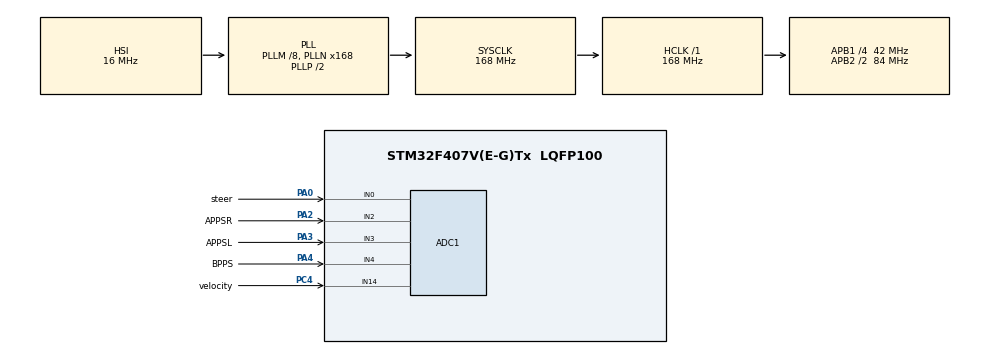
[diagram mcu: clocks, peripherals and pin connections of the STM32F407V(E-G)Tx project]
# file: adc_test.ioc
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ADC1.Channel-0\#ChannelRegularConversion=ADC_CHANNEL_2
ADC1.Channel-1\#ChannelRegularConversion=ADC_CHANNEL_3
ADC1.Channel-2\#ChannelRegularConversion=ADC_CHANNEL_4
ADC1.Channel-3\#ChannelRegularConversion=ADC_CHANNEL_0
ADC1.Channel-4\#ChannelInjectedConversion=ADC_CHANNEL_0
ADC1.Channel-5\#ChannelInjectedConversion=ADC_CHANNEL_0
ADC1.Channel-6\#ChannelInjectedConversion=ADC_CHANNEL_0
ADC1.Channel-7\#ChannelInjectedConversion=ADC_CHANNEL_0
ADC1.ClockPrescaler=ADC_CLOCK_SYNC_PCLK_DIV8
ADC1.ContinuousConvMode=ENABLE
ADC1.DMAContinuousRequests=ENABLE
ADC1.InjNumberOfConversion=4
ADC1.InjectedOffset-4\#ChannelInjectedConversion=0
ADC1.InjectedOffset-5\#ChannelInjectedConversion=0
ADC1.InjectedOffset-6\#ChannelInjectedConversion=0
ADC1.InjectedOffset-7\#ChannelInjectedConversion=0
ADC1.InjectedRank-4\#ChannelInjectedConversion=1
ADC1.InjectedRank-5\#ChannelInjectedConversion=2
ADC1.InjectedRank-6\#ChannelInjectedConversion=3
ADC1.InjectedRank-7\#ChannelInjectedConversion=4
ADC1.NbrOfConversion=4
ADC1.NbrOfConversionFlag=1
ADC1.Rank-0\#ChannelRegularConversion=1
ADC1.Rank-1\#ChannelRegularConversion=2
ADC1.Rank-2\#ChannelRegularConversion=3
ADC1.Rank-3\#ChannelRegularConversion=4
ADC1.SamplingTime-0\#ChannelRegularConversion=ADC_SAMPLETIME_112CYCLES
ADC1.SamplingTime-1\#ChannelRegularConversion=ADC_SAMPLETIME_112CYCLES
ADC1.SamplingTime-2\#ChannelRegularConversion=ADC_SAMPLETIME_112CYCLES
ADC1.SamplingTime-3\#ChannelRegularConversion=ADC_SAMPLETIME_112CYCLES
ADC1.SamplingTime-4\#ChannelInjectedConversion=ADC_SAMPLETIME_3CYCLES
ADC1.SamplingTime-5\#ChannelInjectedConversion=ADC_SAMPLETIME_3CYCLES
ADC1.SamplingTime-6\#ChannelInjectedConversion=ADC_SAMPLETIME_3CYCLES
ADC1.SamplingTime-7\#ChannelInjectedConversion=ADC_SAMPLETIME_3CYCLES
ADC1.ScanConvMode=ENABLE
ADC1.master=1
Dma.ADC1.0.Direction=DMA_PERIPH_TO_MEMORY
Dma.ADC1.0.FIFOMode=DMA_FIFOMODE_DISABLE
Dma.ADC1.0.Instance=DMA2_Stream0
Dma.ADC1.0.MemDataAlignment=DMA_MDATAALIGN_HALFWORD
Dma.ADC1.0.MemInc=DMA_MINC_ENABLE
Dma.ADC1.0.Mode=DMA_CIRCULAR
Dma.ADC1.0.PeriphDataAlignment=DMA_PDATAALIGN_HALFWORD
Dma.ADC1.0.PeriphInc=DMA_PINC_DISABLE
Dma.ADC1.0.Priority=DMA_PRIORITY_LOW
Dma.Request0=ADC1
Mcu.Family=STM32F4
Mcu.Name=STM32F407V(E-G)Tx
Mcu.Package=LQFP100
NVIC.DMA2_Stream0_IRQn=true\:0\:0\:false\:false\:true\:false\:true
NVIC.PriorityGroup=NVIC_PRIORITYGROUP_4
PA0-WKUP.GPIO_Label=steer
PA0-WKUP.Signal=ADCx_IN0
PA2.GPIO_Label=APPSR
PA2.Signal=ADCx_IN2
PA3.GPIO_Label=APPSL
PA3.Signal=ADCx_IN3
PA4.GPIO_Label=BPPS
PA4.Signal=ADCx_IN4
PC4.GPIO_Label=velocity
PC4.Signal=ADCx_IN14
PH0-OSC_IN.Mode=HSE-External-Oscillator
PH0-OSC_IN.Signal=RCC_OSC_IN
PH1-OSC_OUT.Mode=HSE-External-Oscillator
PH1-OSC_OUT.Signal=RCC_OSC_OUT
ProjectManager.HeapSize=0x200
ProjectManager.StackSize=0x400
ProjectManager.TargetToolchain=MDK-ARM V5.32
RCC.48MHZClocksFreq_Value=84000000
RCC.AHBFreq_Value=168000000
RCC.APB1CLKDivider=RCC_HCLK_DIV4
RCC.APB1Freq_Value=42000000
RCC.APB1TimFreq_Value=84000000
RCC.APB2CLKDivider=RCC_HCLK_DIV2
RCC.APB2Freq_Value=84000000
RCC.APB2TimFreq_Value=168000000
RCC.CortexFreq_Value=168000000
RCC.HCLKFreq_Value=168000000
RCC.HSE_VALUE=25000000
RCC.HSI_VALUE=16000000
RCC.LSE_VALUE=32768
RCC.PLLM=8
RCC.PLLN=168
RCC.SYSCLKFreq_VALUE=168000000
RCC.SYSCLKSource=RCC_SYSCLKSOURCE_PLLCLK
RCC.VCOOutputFreq_Value=336000000
SH.ADCx_IN0.0=ADC1_IN0,IN0
SH.ADCx_IN14.0=ADC1_IN14,IN14
SH.ADCx_IN2.0=ADC1_IN2,IN2
SH.ADCx_IN3.0=ADC1_IN3,IN3
SH.ADCx_IN4.0=ADC1_IN4,IN4
board=custom

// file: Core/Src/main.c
/* USER CODE BEGIN Header */
/**
  ******************************************************************************
  * @file           : main.c
  * @brief          : Main program body
  ******************************************************************************
  * @attention
  *
  * <h2><center>&copy; Copyright (c) 2021 STMicroelectronics.
  * All rights reserved.</center></h2>
  *
  * This software component is licensed by ST under BSD 3-Clause license,
  * the "License"; You may not use this file except in compliance with the
  * License. You may obtain a copy of the License at:
  *                        opensource.org/licenses/BSD-3-Clause
  *
  ******************************************************************************
  */
/* USER CODE END Header */
#include "main.h"
#include "adc.h"
#include "dma.h"
#include "gpio.h"

/* USER CODE BEGIN PV */
uint8_t adcArr[4];

/* USER CODE END PV */

void SystemClock_Config(void);

int main(void)
{

  /* MCU Configuration--------------------------------------------------------*/

  /* Reset of all peripherals, Initializes the Flash interface and the Systick. */
  HAL_Init();

  /* Configure the system clock */
  SystemClock_Config();

  /* Initialize all configured peripherals */
  MX_GPIO_Init();
  MX_DMA_Init();
  MX_ADC1_Init();
  /* USER CODE BEGIN 2 */
	HAL_ADC_Start_DMA(&hadc1,(uint32_t*)adcArr,4);
  /* USER CODE END 2 */

  /* Infinite loop */
  while (1)
  {

  }
}

void SystemClock_Config(void)
{
  RCC_OscInitTypeDef RCC_OscInitStruct = {0};
  RCC_ClkInitTypeDef RCC_ClkInitStruct = {0};

  /** Configure the main internal regulator output voltage
  */
  __HAL_RCC_PWR_CLK_ENABLE();
  __HAL_PWR_VOLTAGESCALING_CONFIG(PWR_REGULATOR_VOLTAGE_SCALE1);
  /** Initializes the RCC Oscillators according to the specified parameters
  * in the RCC_OscInitTypeDef structure.
  */
  RCC_OscInitStruct.OscillatorType = RCC_OSCILLATORTYPE_HSI;
  RCC_OscInitStruct.HSIState = RCC_HSI_ON;
  RCC_OscInitStruct.HSICalibrationValue = RCC_HSICALIBRATION_DEFAULT;
  RCC_OscInitStruct.PLL.PLLState = RCC_PLL_ON;
  RCC_OscInitStruct.PLL.PLLSource = RCC_PLLSOURCE_HSI;
  RCC_OscInitStruct.PLL.PLLM = 8;
  RCC_OscInitStruct.PLL.PLLN = 168;
  RCC_OscInitStruct.PLL.PLLP = RCC_PLLP_DIV2;
  RCC_OscInitStruct.PLL.PLLQ = 4;
  if (HAL_RCC_OscConfig(&RCC_OscInitStruct) != HAL_OK)
  {
    Error_Handler();
  }
  /** Initializes the CPU, AHB and APB buses clocks
  */
  RCC_ClkInitStruct.ClockType = RCC_CLOCKTYPE_HCLK|RCC_CLOCKTYPE_SYSCLK
                              |RCC_CLOCKTYPE_PCLK1|RCC_CLOCKTYPE_PCLK2;
  RCC_ClkInitStruct.SYSCLKSource = RCC_SYSCLKSOURCE_PLLCLK;
  RCC_ClkInitStruct.AHBCLKDivider = RCC_SYSCLK_DIV1;
  RCC_ClkInitStruct.APB1CLKDivider = RCC_HCLK_DIV4;
  RCC_ClkInitStruct.APB2CLKDivider = RCC_HCLK_DIV2;

  if (HAL_RCC_ClockConfig(&RCC_ClkInitStruct, FLASH_LATENCY_5) != HAL_OK)
  {
    Error_Handler();
  }
}

void Error_Handler(void)
{
  __disable_irq();
  while (1)
  {
  }
}

/************************ (C) COPYRIGHT STMicroelectronics *****END OF FILE****/
